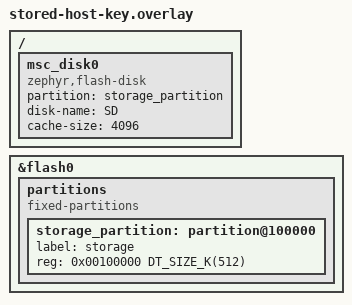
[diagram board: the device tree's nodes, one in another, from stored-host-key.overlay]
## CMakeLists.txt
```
# The wolfSSH provider on a real socket: an image for OpenSSH on the host to reach, and the conformance
# cases of tests/ssh with a scripted client in the same image. scripts/test-ssh-provider.sh drives it.
# Test only. The Access ports here are fakes: see src/test_access_ports.c.
cmake_minimum_required(VERSION 3.20.0)
list(APPEND EXTRA_CONF_FILE
    "${CMAKE_CURRENT_LIST_DIR}/../../../components/ssh/ports/zephyr/wolf-ssh.conf")
# The host key from the credential store on its PSA ports, in place of a key generated at each boot.
option(CRUX_SSH_TEST_STORED_HOST_KEY "Serve the host key from the credential store" OFF)
if(CRUX_SSH_TEST_STORED_HOST_KEY)
    list(APPEND EXTRA_CONF_FILE "${CMAKE_CURRENT_LIST_DIR}/stored-host-key.conf")
    list(APPEND EXTRA_DTC_OVERLAY_FILE "${CMAKE_CURRENT_LIST_DIR}/stored-host-key.overlay")
endif()
find_package(Zephyr REQUIRED HINTS $ENV{ZEPHYR_BASE})
project(crux_ssh_provider_test)

include(../../../components/ssh/ports/zephyr/wolf_ssh_settings.cmake)
crux_ssh_wolf_settings()
target_compile_definitions(crux_ssh_wolf_provider PRIVATE CRUX_SSH_WOLF_TESTING=1)
if(DEFINED CRUX_SSH_TEST_WINDOW_BYTES)
    target_compile_definitions(crux_ssh_wolf_provider PRIVATE
        CRUX_SSH_WOLF_WINDOW_BYTES=${CRUX_SSH_TEST_WINDOW_BYTES})
endif()
if(CRUX_SSH_TEST_OFFER_MLKEM)
    target_compile_definitions(crux_ssh_wolf_provider PRIVATE CRUX_SSH_WOLF_OFFER_MLKEM=1)
endif()

set(repository "${CMAKE_CURRENT_LIST_DIR}/../../..")
target_sources(app PRIVATE
    src/main.c
    src/test_access_ports.c
    src/test_keys.c
    src/test_sessions.c
    "${repository}/components/access/src/access.c"
    "${repository}/components/access/src/access_accounts.c"
    "${repository}/components/access/src/access_delay.c"
    "${repository}/components/access/src/access_login.c"
    "${repository}/components/access/src/access_record.c"
    "${repository}/components/access/src/access_session.c")
target_include_directories(app PRIVATE
    src
    "${repository}/components/access/include"
    "${repository}/components/access/adapter"
    "${repository}/components/access/src"
    "${repository}/components/ssh/adapter"
    "${repository}/components/ssh/ports/zephyr")
target_compile_definitions(app PRIVATE CRUX_SSH_WOLF_TESTING=1)
target_link_libraries(app PRIVATE crux::sync)

if(CRUX_SSH_TEST_STORED_HOST_KEY)
    if(NOT CONFIG_BOARD_NATIVE_SIM OR NOT CONFIG_WOLFPSA)
        message(FATAL_ERROR "The stored host key image is for native_sim on wolfPSA: its random "
                            "numbers come from a test generator")
    endif()
    # One wolfCrypt under wolfPSA and wolfSSH, as in tests/native/management_composition.
    include("${repository}/tests/psa_crypto/provider_declarations.cmake")
    target_compile_definitions(wolfSSL INTERFACE ${CRUX_PSA_WOLFCRYPT_DEFINITIONS})
    include("${repository}/components/ssh/access/sources.cmake")
    target_sources(app PRIVATE
        src/stored_host_key.c
        ${CRUX_SSH_HOST_KEY_SOURCES}
        "${repository}/components/credential/src/credential_image.c"
        "${repository}/components/credential/src/credential_store.c"
        "${repository}/components/credential/ports/psa/credential_psa.c"
        "${repository}/components/credential/ports/zephyr/credential_device_id.c")
    target_include_directories(app PRIVATE
        ${CRUX_SSH_HOST_KEY_INCLUDES}
        "${repository}/components/credential/src"
        "${repository}/components/credential/ports/psa"
        "${repository}/components/file/ports/zephyr")
    target_compile_definitions(app PRIVATE CRUX_SSH_TEST_STORED_HOST_KEY=1)
    target_link_libraries(app PRIVATE crux::file)
endif()

# The scripted client and the cases run on the host-reachable socket, so only on native_sim.
if(CONFIG_ARCH_POSIX)
    target_sources(app PRIVATE src/conformance_client.c "${repository}/tests/ssh/conformance.c")
    target_include_directories(app PRIVATE "${repository}/tests/ssh")
endif()
```

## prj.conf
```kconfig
# Shared by every build of this test image. Each stack and the arena are for this test: see
# docs/ssh-wolf-provider.md for what they were measured to need.
CONFIG_MAIN_STACK_SIZE=32768
CONFIG_COMMON_LIBC_MALLOC_ARENA_SIZE=524288
CONFIG_SYS_HEAP_RUNTIME_STATS=y
CONFIG_INIT_STACKS=y
CONFIG_THREAD_STACK_INFO=y
CONFIG_NETWORKING=y
CONFIG_NET_IPV4=y
CONFIG_NET_IPV6=n
CONFIG_NET_TCP=y
CONFIG_NET_SOCKETS=y
CONFIG_ZVFS_OPEN_MAX=32
CONFIG_ZVFS_POLL_MAX=8
CONFIG_NET_MAX_CONTEXTS=16
CONFIG_NET_SOCKETS_SOCKOPT_TLS=n
CONFIG_TLS_CREDENTIALS=n
CONFIG_MBEDTLS=n
CONFIG_CRUX_SYNC=y
CONFIG_CRUX_SYNC_MUTEX_COUNT=8
CONFIG_TEST_RANDOM_GENERATOR=y
```

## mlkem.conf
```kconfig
# Offers mlkem768x25519-sha256, to measure its cost. Off by default: see docs/ssh-wolf-provider.md.
CONFIG_WOLFSSL_MLKEM=y
```

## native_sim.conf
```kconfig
# The SSH test image on native_sim, as in tests/zephyr/ssh_wolf_probe: wolfSSH without the TLS socket
# backend on an unpatched Zephyr, and OpenSSH on the host reaching it through the native socket offload.
CONFIG_POSIX_API=n
CONFIG_POSIX_TIMERS=n
CONFIG_POSIX_THREADS=n
CONFIG_POSIX_SYSTEM_INTERFACES=y
CONFIG_NET_DRIVERS=y
CONFIG_NET_SOCKETS_OFFLOAD=y
CONFIG_NET_NATIVE_OFFLOADED_SOCKETS=y
CONFIG_ETH_NATIVE_TAP=n
# Sim time must follow the wall clock, or a limit would pass in no time for a client on the host.
CONFIG_NATIVE_SIM_SLOWDOWN_TO_REAL_TIME=y
```

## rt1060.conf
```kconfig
# RT1060-EVKB, compile only. No image from this build is flashed or run.
CONFIG_POSIX_API=y
CONFIG_POSIX_TIMERS=y
CONFIG_POSIX_THREADS=y
CONFIG_NET_L2_ETHERNET=y
CONFIG_ETH_DRIVER=y
```

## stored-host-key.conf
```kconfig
# Added by -DCRUX_SSH_TEST_STORED_HOST_KEY=ON, on native_sim only: the host key from the credential store
# on its PSA ports over wolfPSA, and the store on FatFs over the flash simulator's host file. TEST ONLY:
# the random numbers come from native_sim's test generator. See docs/ssh-wolf-provider.md.
CONFIG_PSA_CRYPTO=y
CONFIG_PSA_CRYPTO_PROVIDER_CUSTOM=y
CONFIG_PSA_WANT_ALG_SHA_256=y
CONFIG_PSA_WANT_ALG_GCM=y
CONFIG_PSA_WANT_KEY_TYPE_AES=y
CONFIG_PSA_WANT_ALG_ECDSA=y
CONFIG_PSA_WANT_KEY_TYPE_ECC_PUBLIC_KEY=y
CONFIG_PSA_WANT_KEY_TYPE_ECC_KEY_PAIR_IMPORT=y
CONFIG_PSA_WANT_KEY_TYPE_ECC_KEY_PAIR_EXPORT=y
CONFIG_PSA_WANT_KEY_TYPE_ECC_KEY_PAIR_GENERATE=y
CONFIG_PSA_WANT_ECC_SECP_R1_256=y
CONFIG_HWINFO=y

CONFIG_FILE_SYSTEM=y
CONFIG_FILE_SYSTEM_MKFS=y
CONFIG_FAT_FILESYSTEM_ELM=y
CONFIG_FS_FATFS_LFN=y
CONFIG_FS_FATFS_LFN_MODE_STACK=y
CONFIG_FS_FATFS_MAX_LFN=127
CONFIG_FS_FATFS_MOUNT_MKFS=n
CONFIG_FS_FATFS_REENTRANT=y
CONFIG_FS_FATFS_NUM_FILES=6
CONFIG_DISK_DRIVERS=y
CONFIG_DISK_DRIVER_FLASH=y
CONFIG_CRUX_FILE_FATFS_SIMULATOR=y
```

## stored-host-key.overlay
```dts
/* SPDX-License-Identifier: Apache-2.0 */
/* Added by -DCRUX_SSH_TEST_STORED_HOST_KEY=ON: a disk on the flash simulator, backed by a host file,
 * so that the credential store outlives each process. */
/delete-node/ &storage_partition;

&flash0 {
    partitions {
        compatible = "fixed-partitions";
        #address-cells = <1>;
        #size-cells = <1>;

        storage_partition: partition@100000 {
            label = "storage";
            reg = <0x00100000 DT_SIZE_K(512)>;
        };
    };
};

/ {
    msc_disk0 {
        status = "okay";
        compatible = "zephyr,flash-disk";
        partition = <&storage_partition>;
        disk-name = "SD";
        cache-size = <4096>;
    };
};
```

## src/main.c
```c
/*
 * The test image. With no arguments it serves SSH for scripts/test-ssh-provider.sh, with the access
 * adapter of #192 on the test ports, and stand-ins for the CLI and SFTP. With "conformance" it runs
 * the cases of tests/ssh on the provider with a scripted client. TEST ONLY. It prints what a test
 * on the host reads, and it is never flashed or run on a board.
 */
#include "crux_access_adapter.h"
#include "crux_ssh_callbacks.h"
#include "crux_ssh_wolf_provider.h"
#include "test_support.h"

#include <zephyr/kernel.h>
#include <zephyr/sys/printk.h>

#include <stdlib.h>
#include <string.h>

#ifdef CONFIG_ARCH_POSIX
#include "cmdline.h"
#include "nsi_main.h"
#endif

#define KEYS_MAX 4
#define KEY_BLOB_MAX 192u

static const char *const administrator_permissions[] = {CRUX_ACCESS_PERMISSION_MANAGE};
static const crux_access_role_t roles[] = {{"administrator", administrator_permissions, 1}};
static const crux_access_policy_t policy = {roles, 1, 15u * 60u, 8u * 3600u, NULL};

static struct {
    const char *mode;
    const char *only_case;
    const char *user;
    const char *password;
    const char *keys[KEYS_MAX];
    size_t key_count;
    crux_ssh_key_type_t host_key_type;
    bool repository_stand_ins;
    bool format;
    crux_ssh_config_t config;
} options = {
    .mode = "serve",
    .user = "operator",
    .password = "correct horse battery",
    .host_key_type = CRUX_SSH_KEY_ED25519,
    .config = {.port = 2222,
               .max_connections = 2,
               .max_auth_attempts = 3,
               .auth_timeout_ms = 3000,
               .io_timeout_ms = 200},
};

static test_key_t host_key;

static void finish(int status)
{
    printk("EXIT %d\n", status);
#ifdef CONFIG_ARCH_POSIX
    nsi_exit(status);
#endif
}

#ifdef CONFIG_ARCH_POSIX
static void parse_arguments(void)
{
    int argc = 0;
    char **argv = NULL;

    native_get_test_cmd_line_args(&argc, &argv);
    for (int i = 0; i < argc; ++i) {
        const char *value = strchr(argv[i], '=');

        value = value != NULL ? value + 1 : "";
        if (strcmp(argv[i], "conformance") == 0) {
            options.mode = "conformance";
        } else if (strncmp(argv[i], "only=", 5) == 0) {
            options.only_case = value;
        } else if (strncmp(argv[i], "key=", 4) == 0 && options.key_count < KEYS_MAX) {
            options.keys[options.key_count++] = value;
        } else if (strcmp(argv[i], "host=ecdsa") == 0) {
            options.host_key_type = CRUX_SSH_KEY_ECDSA_P256;
        } else if (strcmp(argv[i], "format") == 0) {
            options.format = true;
        } else if (strcmp(argv[i], "stand-ins=repository") == 0) {
            options.repository_stand_ins = true;
        } else if (strncmp(argv[i], "connections=", 12) == 0) {
            options.config.max_connections = (uint8_t)atoi(value);
        } else if (strncmp(argv[i], "attempts=", 9) == 0) {
            options.config.max_auth_attempts = (uint8_t)atoi(value);
        } else if (strncmp(argv[i], "send-block=", 11) == 0) {
            crux_ssh_wolf_test_block_sends((unsigned)atoi(value));
        } else if (strncmp(argv[i], "auth-ms=", 8) == 0) {
            options.config.auth_timeout_ms = (uint32_t)atoi(value);
        }
    }
}
#else
static void parse_arguments(void)
{
}
#endif

static int hex_value(char digit)
{
    if (digit >= '0' && digit <= '9') {
        return digit - '0';
    }
    return digit >= 'a' && digit <= 'f' ? digit - 'a' + 10 : -1;
}

static size_t decode_hex(const char *text, uint8_t *out, size_t capacity)
{
    size_t length = strlen(text) / 2u;

    if (length > capacity) {
        return 0u;
    }
    for (size_t i = 0; i < length; ++i) {
        int high = hex_value(text[2u * i]);
        int low = hex_value(text[2u * i + 1u]);

        if (high < 0 || low < 0) {
            return 0u;
        }
        out[i] = (uint8_t)(high * 16 + low);
    }
    return length;
}

static bool set_up_accounts(void)
{
    static const crux_access_origin_t serial = {.channel = CRUX_ACCESS_CHANNEL_SERIAL};
    crux_access_session_t session = {0};
    uint32_t retry_after_ms = 0;
    size_t password_length = strlen(options.password);

    if (crux_access_init(&policy) != CRUX_ACCESS_OK ||
        crux_access_provision_first_account(options.user, options.password, password_length,
                                            "administrator", &serial) != CRUX_ACCESS_OK ||
        crux_access_login_password(options.user, options.password, password_length, &serial,
                                   &session, &retry_after_ms) != CRUX_ACCESS_OK) {
        return false;
    }
    for (size_t i = 0; i < options.key_count; ++i) {
        uint8_t blob[KEY_BLOB_MAX];
        size_t length = decode_hex(options.keys[i], blob, sizeof(blob));

        if (length == 0u ||
            crux_access_account_add_key(session, options.user, blob, length) != CRUX_ACCESS_OK) {
            return false;
        }
    }
    crux_access_logout(&session);
    return true;
}

static bool host_key_ready(void)
{
#ifdef CRUX_SSH_TEST_STORED_HOST_KEY
    return test_stored_host_key_load(options.host_key_type, options.format, &host_key);
#else
    return test_key_generate(options.host_key_type, &host_key);
#endif
}

static int serve(void)
{
    crux_ssh_callbacks_t callbacks = *crux_ssh_callback_table();
    crux_status_t status;

    if (!set_up_accounts() || !host_key_ready()) {
        printk("SETUP failed\n");
        return 2;
    }
    if (!options.repository_stand_ins) {
        test_sessions_fill(&callbacks);
    }
    options.config.host_key_type = host_key.type;
    options.config.host_key = host_key.host_key;
    options.config.host_key_length = host_key.host_key_length;
    test_key_print_fingerprint(&host_key);
    status = crux_ssh_wolf_provider()->start(&options.config, &callbacks);
    if (status != CRUX_OK) {
        printk("START failed %d\n", (int)status);
        return 3;
    }
    printk("READY port=%u\n", options.config.port);
    test_sessions_wait_for_stop();
    status = crux_ssh_wolf_provider()->stop();
    printk("STOPPED %d\n", (int)status);
    test_print_measurements();
    return status == CRUX_OK ? 0 : 4;
}

int main(void)
{
    parse_arguments();
#ifdef CONFIG_ARCH_POSIX
    if (strcmp(options.mode, "conformance") == 0) {
        finish(test_conformance_run(options.only_case));
        return 0;
    }
#endif
    finish(serve());
    return 0;
}
```

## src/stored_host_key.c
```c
/*
 * The host key from the credential store, for an image built with CRUX_SSH_TEST_STORED_HOST_KEY.
 * The store runs on its PSA ports over wolfPSA, on FatFs over the flash simulator, whose host file
 * outlives the process, so a test boots the image again on the same file and sees the same key.
 *
 * TEST ONLY. The random numbers come from native_sim's test generator and the device ID from its
 * hwinfo, so a stored key here protects nothing: see docs/psa-crypto-design.md. The image prints
 * the store's events and the fingerprint, and never the key.
 */
#include "credential_port.h"
#include "crux_ssh_access.h"
#include "file_native.h"
#include "test_support.h"

#include <crux_credential_adapter.h>

#include <ff.h>
#include <string.h>
#include <zephyr/fs/fs.h>
#include <zephyr/sys/printk.h>

enum { ROOT_SLOT_A = 1, ROOT_SLOT_B = 2 };
#define MOUNT_POINT "/SD:"
#define DISK_NAME "SD:"
#define PATH_SLOT_A MOUNT_POINT "/secure-a"
#define PATH_SLOT_B MOUNT_POINT "/secure-b"

static FATFS fat;
static struct fs_mount_t mount = {
    .type = FS_FATFS,
    .mnt_point = MOUNT_POINT,
    .fs_data = &fat,
    .flags = FS_MOUNT_FLAG_NO_FORMAT,
};

/* The store's events, which carry no record bytes, for the test on the host to read. */
void crux_credential_port_event(const crux_credential_event_t *event)
{
    static const char *const names[] = {"state",         "slot_invalid", "save_failed",
                                        "key_generated", "key_replaced", "erased"};
    const char *name =
        (size_t)event->type < sizeof(names) / sizeof(names[0]) ? names[event->type] : "unknown";

    printk("STORE event=credential.%s record=%d result=%d state=%d\n", name, (int)event->record,
           (int)event->result, (int)event->state);
}

static bool directory_ready(const char *path)
{
    int result = fs_mkdir(path);

    return result == 0 || result == -EEXIST;
}

/* Formats a blank disk only when the test asks, so that a test can also boot on a disk that does
 * not mount and see the store refuse. */
static bool medium_ready(bool format)
{
    if (fs_mount(&mount) != 0) {
        if (!format || fs_mkfs(FS_FATFS, (uintptr_t)DISK_NAME, NULL, 0) != 0 ||
            fs_mount(&mount) != 0) {
            return false;
        }
    }
    return directory_ready(PATH_SLOT_A) && directory_ready(PATH_SLOT_B) &&
           crux_file_zephyr_bind_root(ROOT_SLOT_A, PATH_SLOT_A) == CRUX_FILE_OK &&
           crux_file_zephyr_bind_root(ROOT_SLOT_B, PATH_SLOT_B) == CRUX_FILE_OK;
}

bool test_stored_host_key_load(crux_ssh_key_type_t type, bool format, test_key_t *key)
{
    crux_ssh_host_key_t host_key;
    crux_credential_result_t store;
    crux_status_t status;

    /* A medium that failed leaves the roots unbound, and the store then reads UNUSABLE. */
    if (!medium_ready(format)) {
        printk("STORE medium not ready\n");
    }
    store = crux_credential_start(ROOT_SLOT_A, ROOT_SLOT_B);
    printk("STORE start=%d state=%d\n", (int)store, (int)crux_credential_state());
    status = crux_ssh_host_key_load(type, &host_key);
    if (status != CRUX_OK) {
        printk("HOST-KEY unavailable status=%d\n", (int)status);
        return false;
    }
    memset(key, 0, sizeof(*key));
    key->type = host_key.type;
    key->host_key_length = host_key.length;
    memcpy(key->host_key, host_key.key, host_key.length);
    crux_ssh_host_key_clear(&host_key);
    return true;
}
```

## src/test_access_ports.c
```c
/*
 * crux_access ports for this test image: TEST ONLY, and declared as such in
 * docs/ssh-wolf-provider.md. The store is RAM, so accounts last one run. Random numbers come from
 * native_sim's test generator. The derivation and the keyed hash are real wolfCrypt, because a
 * client on the host needs a real login path, and neither is the PSA provider that #242 supplies.
 * Events print, so that a test on the host can read them.
 */
#include "test_support.h"

#include "access_port.h"

#include <zephyr/kernel.h>
#include <zephyr/random/random.h>
#include <zephyr/sys/printk.h>

#include <wolfssl/wolfcrypt/hmac.h>
#include <wolfssl/wolfcrypt/pwdbased.h>

#include <string.h>

static uint8_t record_bytes[CRUX_ACCESS_RECORD_SIZE_MAX];
static size_t record_length;
static int32_t derive_delay_ms;
static unsigned derive_count;

void test_access_derive_delay_ms(int32_t delay_ms)
{
    derive_delay_ms = delay_ms;
}

unsigned test_access_derive_count(void)
{
    return derive_count;
}

bool crux_access_port_derive(uint32_t algorithm, uint32_t iterations,
                             const uint8_t salt[CRUX_ACCESS_SALT_SIZE], const char *password,
                             size_t length, uint8_t derived[CRUX_ACCESS_DERIVED_SIZE])
{
    ++derive_count;
    printk("ACCESS derive count=%u\n", derive_count);
    if (algorithm != CRUX_ACCESS_VERIFIER_PBKDF2_HMAC_SHA256) {
        return false;
    }
    /* CPU work takes no simulated time, so a slow verifier on a board is modelled by a sleep. */
    if (derive_delay_ms > 0) {
        k_msleep(derive_delay_ms);
    }
    return wc_PBKDF2(derived, (const byte *)password, (int)length, salt, CRUX_ACCESS_SALT_SIZE,
                     (int)iterations, CRUX_ACCESS_DERIVED_SIZE, WC_SHA256) == 0;
}

bool crux_access_port_random(uint8_t *output, size_t length)
{
    sys_rand_get(output, length);
    return true;
}

bool crux_access_port_hmac(const uint8_t key[CRUX_ACCESS_HASH_KEY_SIZE], const uint8_t *data,
                           size_t length, uint8_t hash[CRUX_ACCESS_HASH_SIZE])
{
    Hmac hmac;
    int result = wc_HmacInit(&hmac, NULL, INVALID_DEVID);

    if (result == 0) {
        result = wc_HmacSetKey(&hmac, WC_SHA256, key, CRUX_ACCESS_HASH_KEY_SIZE);
    }
    if (result == 0) {
        result = wc_HmacUpdate(&hmac, data, (word32)length);
    }
    if (result == 0) {
        result = wc_HmacFinal(&hmac, hash);
    }
    wc_HmacFree(&hmac);
    return result == 0;
}

uint64_t crux_access_port_now_ms(void)
{
    return (uint64_t)k_uptime_get();
}

crux_access_store_state_t crux_access_port_store_load(uint8_t *record, size_t capacity,
                                                      size_t *length)
{
    if (record_length == 0u) {
        return CRUX_ACCESS_STORE_EMPTY;
    }
    if (record_length > capacity) {
        return CRUX_ACCESS_STORE_UNUSABLE;
    }
    memcpy(record, record_bytes, record_length);
    *length = record_length;
    return CRUX_ACCESS_STORE_VALID;
}

bool crux_access_port_store_save(const uint8_t *record, size_t length)
{
    if (length > sizeof(record_bytes)) {
        return false;
    }
    memcpy(record_bytes, record, length);
    record_length = length;
    return true;
}

static const char *event_name(crux_access_event_type_t type)
{
    switch (type) {
    case CRUX_ACCESS_EVENT_LOGIN_SUCCESS:
        return "LOGIN_SUCCESS";
    case CRUX_ACCESS_EVENT_LOGIN_FAILURE:
        return "LOGIN_FAILURE";
    case CRUX_ACCESS_EVENT_KEY_FAILURE:
        return "KEY_FAILURE";
    case CRUX_ACCESS_EVENT_DELAY_APPLIED:
        return "DELAY_APPLIED";
    case CRUX_ACCESS_EVENT_LOGOUT:
        return "LOGOUT";
    case CRUX_ACCESS_EVENT_LOGIN_BUSY:
        return "LOGIN_BUSY";
    case CRUX_ACCESS_EVENT_LOGIN_NO_SESSION:
        return "LOGIN_NO_SESSION";
    case CRUX_ACCESS_EVENT_LOGIN_REFUSED:
        return "LOGIN_REFUSED";
    default:
        return "OTHER";
    }
}

void crux_access_port_event(const crux_access_event_t *event)
{
    printk("ACCESS event type=%s result=%d channel=%d source_length=%u account=%s\n",
           event_name(event->type), (int)event->result, (int)event->origin.channel,
           (unsigned)event->origin.source_length, event->account);
}
```

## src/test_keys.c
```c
/* Host and user keys for this test image, generated at each boot. TEST ONLY. */
#include "crux_ssh_wolf_provider.h"
#include "test_support.h"

#include <zephyr/sys/byteorder.h>
#include <zephyr/sys/printk.h>

#include <wolfssl/wolfcrypt/asn_public.h>
#include <wolfssl/wolfcrypt/ecc.h>
#include <wolfssl/wolfcrypt/ed25519.h>
#include <wolfssl/wolfcrypt/hash.h>
#include <wolfssl/wolfcrypt/random.h>
#include <wolfssl/wolfcrypt/sha256.h>

#include <string.h>

static WC_RNG rng;
static bool rng_ready;

static bool rng_get(void)
{
    if (!rng_ready) {
        rng_ready = wc_InitRng(&rng) == 0;
    }
    return rng_ready;
}

static size_t put_string(uint8_t *out, const void *text, size_t length)
{
    sys_put_be32((uint32_t)length, out);
    memcpy(out + 4, text, length);
    return 4u + length;
}

static bool generate_ed25519(test_key_t *key)
{
    ed25519_key wolf_key;
    word32 private_length = 32u;
    word32 public_length = 32u;
    bool done;

    if (wc_ed25519_init(&wolf_key) != 0) {
        return false;
    }
    done = wc_ed25519_make_key(&rng, ED25519_KEY_SIZE, &wolf_key) == 0 &&
           wc_ed25519_export_private_only(&wolf_key, key->host_key, &private_length) == 0 &&
           wc_ed25519_export_public(&wolf_key, key->host_key + 32, &public_length) == 0;
    wc_ed25519_free(&wolf_key);
    key->host_key_length = 64u;
    key->blob_length = put_string(key->blob, "ssh-ed25519", 11u);
    key->blob_length += put_string(key->blob + key->blob_length, key->host_key + 32, 32u);
    return done;
}

static bool generate_p256(test_key_t *key)
{
    ecc_key wolf_key;
    word32 private_length = 32u;
    word32 public_length = 65u;
    bool done;

    if (wc_ecc_init(&wolf_key) != 0) {
        return false;
    }
    done = wc_ecc_make_key_ex(&rng, 32, &wolf_key, ECC_SECP256R1) == 0 &&
           wc_ecc_export_private_only(&wolf_key, key->host_key, &private_length) == 0 &&
           private_length == 32u &&
           wc_ecc_export_x963(&wolf_key, key->host_key + 32, &public_length) == 0;
    wc_ecc_free(&wolf_key);
    key->host_key_length = 97u;
    key->blob_length = put_string(key->blob, "ecdsa-sha2-nistp256", 19u);
    key->blob_length += put_string(key->blob + key->blob_length, "nistp256", 8u);
    key->blob_length += put_string(key->blob + key->blob_length, key->host_key + 32, 65u);
    return done;
}

bool test_key_generate(crux_ssh_key_type_t type, test_key_t *key)
{
    memset(key, 0, sizeof(*key));
    key->type = type;
    if (!rng_get()) {
        return false;
    }
    return type == CRUX_SSH_KEY_ED25519 ? generate_ed25519(key) : generate_p256(key);
}

static bool sign_ed25519(const test_key_t *key, const uint8_t *data, size_t length, uint8_t *out,
                         word32 *out_length)
{
    ed25519_key wolf_key;
    bool done;

    if (wc_ed25519_init(&wolf_key) != 0) {
        return false;
    }
    done = wc_ed25519_import_private_key(key->host_key, 32u, key->host_key + 32, 32u, &wolf_key) ==
               0 &&
           wc_ed25519_sign_msg(data, (word32)length, out, out_length, &wolf_key) == 0;
    wc_ed25519_free(&wolf_key);
    return done;
}

static size_t put_mpint(uint8_t *out, const uint8_t *value, size_t length)
{
    size_t lead = (length > 0u && (value[0] & 0x80u) != 0u) ? 1u : 0u;

    sys_put_be32((uint32_t)(length + lead), out);
    out[4] = 0u;
    memcpy(out + 4 + lead, value, length);
    return 4u + lead + length;
}

static bool sign_p256(const test_key_t *key, const uint8_t *data, size_t length, uint8_t *out,
                      word32 *out_length, bool good_signature)
{
    ecc_key wolf_key;
    uint8_t digest[WC_SHA256_DIGEST_SIZE];
    uint8_t der[80];
    uint8_t r[33];
    uint8_t s[33];
    word32 der_length = sizeof(der);
    word32 r_length = sizeof(r);
    word32 s_length = sizeof(s);
    bool done;

    if (wc_ecc_init(&wolf_key) != 0) {
        return false;
    }
    done = wc_Sha256Hash(data, (word32)length, digest) == 0 &&
           wc_ecc_import_private_key_ex(key->host_key, 32u, key->host_key + 32, 65u, &wolf_key,
                                        ECC_SECP256R1) == 0 &&
           wc_ecc_set_rng(&wolf_key, &rng) == 0 &&
           wc_ecc_sign_hash(digest, sizeof(digest), der, &der_length, &rng, &wolf_key) == 0 &&
           wc_ecc_sig_to_rs(der, der_length, r, &r_length, s, &s_length) == 0;
    wc_ecc_free(&wolf_key);
    if (!done) {
        return false;
    }
    if (!good_signature) {
        r[r_length - 1u] ^= 0x01u;
    }
    *out_length = (word32)put_mpint(out, r, r_length);
    *out_length += (word32)put_mpint(out + *out_length, s, s_length);
    return true;
}

bool test_key_sign(const test_key_t *key, const char *algorithm, const uint8_t *data, size_t length,
                   bool good_signature, uint8_t *signature, size_t capacity, size_t *written)
{
    uint8_t body[96];
    word32 body_length = sizeof(body);
    size_t at;

    if (key->type == CRUX_SSH_KEY_ED25519) {
        if (!sign_ed25519(key, data, length, body, &body_length)) {
            return false;
        }
        if (!good_signature) {
            body[body_length - 1u] ^= 0x01u;
        }
    } else if (!sign_p256(key, data, length, body, &body_length, good_signature)) {
        return false;
    }
    if (capacity < 8u + strlen(algorithm) + body_length) {
        return false;
    }
    at = put_string(signature, algorithm, strlen(algorithm));
    at += put_string(signature + at, body, body_length);
    *written = at;
    return true;
}

void test_key_print_fingerprint(const test_key_t *key)
{
    char fingerprint[CRUX_SSH_WOLF_FINGERPRINT_SIZE];

    if (crux_ssh_wolf_host_key_fingerprint(key->type, key->host_key, key->host_key_length,
                                           fingerprint, sizeof(fingerprint)) == CRUX_OK) {
        printk("HOST-KEY %s\n", fingerprint);
    } else {
        printk("HOST-KEY unavailable\n");
    }
}
```

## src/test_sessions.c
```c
/*
 * Stand-ins for the CLI of #193 and the SFTP adapter of #194, so that OpenSSH can exercise the
 * channel functions, the exit status and the close. TEST ONLY: none of these commands exists in
 * Crux.
 */
#include "crux_ssh_attachment.h"
#include "crux_ssh_wolf_provider.h"
#include "test_support.h"

#include <zephyr/kernel.h>
#include <zephyr/sys/printk.h>
#include <zephyr/sys/sys_heap.h>

#include <stdlib.h>
#include <string.h>

struct crux_ssh_file_handle {
    int id;
};

/* In Zephyr's malloc.c, with no header of its own at this revision. */
int malloc_runtime_stats_get(struct sys_memory_stats *stats);

static K_SEM_DEFINE(stop_requested, 0, 1);
static struct crux_ssh_file_handle file_handles[CRUX_SSH_WOLF_CONNECTIONS_MAX];
static atomic_t next_handle;

static crux_status_t write_all(crux_ssh_channel_t *channel, const void *data, size_t length)
{
    const crux_ssh_provider_t *provider = crux_ssh_wolf_provider();
    const char *at = data;

    while (length > 0u) {
        size_t written = 0;
        crux_status_t status = provider->write(channel, at, length, &written);

        if (status == CRUX_ERR_TIMEOUT) {
            continue;
        }
        if (status != CRUX_OK) {
            return status;
        }
        at += written;
        length -= written;
    }
    return CRUX_OK;
}

static crux_status_t write_text(crux_ssh_channel_t *channel, const char *text)
{
    return write_all(channel, text, strlen(text));
}

static int echo_until_end(crux_ssh_channel_t *channel)
{
    const crux_ssh_provider_t *provider = crux_ssh_wolf_provider();
    char buffer[256];

    while (true) {
        size_t count = 0;
        crux_status_t status = provider->read(channel, buffer, sizeof(buffer), &count);

        if (status == CRUX_ERR_TIMEOUT) {
            continue;
        }
        if (status != CRUX_OK) {
            return status == CRUX_ERR_NO_DATA ? 0 : 1;
        }
        if (write_all(channel, buffer, count) != CRUX_OK) {
            return 1;
        }
    }
}

static int send_pattern(crux_ssh_channel_t *channel, size_t length)
{
    char block[512];

    for (size_t i = 0; i < sizeof(block); ++i) {
        block[i] = (char)('a' + i % 26u);
    }
    while (length > 0u) {
        size_t piece = MIN(length, sizeof(block));

        if (write_all(channel, block, piece) != CRUX_OK) {
            return 1;
        }
        length -= piece;
    }
    return 0;
}

static int print_user(crux_ssh_attachment_t *attachment, crux_ssh_channel_t *channel)
{
    crux_access_session_t session = crux_ssh_attachment_session(attachment);
    char user[CRUX_ACCESS_NAME_SIZE];
    char role[CRUX_ACCESS_NAME_SIZE];

    if (crux_access_session_user(session, user, sizeof(user)) != CRUX_ACCESS_OK ||
        crux_access_session_role(session, role, sizeof(role)) != CRUX_ACCESS_OK) {
        return 1;
    }
    (void)write_text(channel, user);
    (void)write_text(channel, " ");
    (void)write_text(channel, role);
    (void)write_text(channel, "\n");
    return 0;
}

void test_print_measurements(void)
{
    struct sys_memory_stats stats = {0};
    size_t worker = 0;
    size_t listener = 0;

    (void)malloc_runtime_stats_get(&stats);
    crux_ssh_wolf_test_stack_used(&worker, &listener);
    printk("MEASURE heap_allocated=%zu heap_peak=%zu heap_free=%zu worker_stack_used=%zu "
           "listener_stack_used=%zu\n",
           stats.allocated_bytes, stats.max_allocated_bytes, stats.free_bytes, worker, listener);
}

static int test_exec(void *context, crux_ssh_attachment_t *attachment, crux_ssh_channel_t *channel,
                     const char *command, size_t command_length)
{
    ARG_UNUSED(context);
    ARG_UNUSED(command_length);
    if (strcmp(command, "whoami") == 0) {
        return print_user(attachment, channel);
    }
    if (strncmp(command, "exit ", 5) == 0) {
        return atoi(command + 5);
    }
    if (strncmp(command, "output ", 7) == 0) {
        return send_pattern(channel, (size_t)atoi(command + 7));
    }
    if (strcmp(command, "cat") == 0) {
        return echo_until_end(channel);
    }
    if (strncmp(command, "sleep ", 6) == 0) {
        k_msleep(atoi(command + 6));
        return 0;
    }
    if (strncmp(command, "derive-delay ", 13) == 0) {
        test_access_derive_delay_ms(atoi(command + 13));
        return 0;
    }
    if (strcmp(command, "measure") == 0) {
        test_print_measurements();
        return 0;
    }
    if (strcmp(command, "stop") == 0) {
        k_sem_give(&stop_requested);
        return 0;
    }
    (void)write_text(channel, "unknown test command\n");
    return 127;
}

static int test_shell(void *context, crux_ssh_attachment_t *attachment, crux_ssh_channel_t *channel,
                      bool terminal)
{
    ARG_UNUSED(context);
    ARG_UNUSED(attachment);
    (void)write_text(channel, terminal ? "terminal=1\r\n" : "terminal=0\n");
    return echo_until_end(channel);
}

static crux_status_t test_sftp_open(void *context, crux_ssh_attachment_t *attachment,
                                    crux_ssh_file_handle_t **handle)
{
    ARG_UNUSED(context);
    ARG_UNUSED(attachment);
    /* Every operation of the refusing port in components/ssh/sftp/port fails behind this handle. */
    *handle = &file_handles[(size_t)atomic_inc(&next_handle) % ARRAY_SIZE(file_handles)];
    printk("SFTP open\n");
    return CRUX_OK;
}

static void test_sftp_close(void *context, crux_ssh_attachment_t *attachment,
                            crux_ssh_file_handle_t *handle)
{
    ARG_UNUSED(context);
    ARG_UNUSED(attachment);
    ARG_UNUSED(handle);
    printk("SFTP close\n");
}

void test_sessions_fill(crux_ssh_callbacks_t *callbacks)
{
    callbacks->shell = test_shell;
    callbacks->exec = test_exec;
    callbacks->sftp_open = test_sftp_open;
    callbacks->sftp_close = test_sftp_close;
}

void test_sessions_wait_for_stop(void)
{
    (void)k_sem_take(&stop_requested, K_FOREVER);
}
```

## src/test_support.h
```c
/* What the parts of this test image share. Test only. */
#ifndef CRUX_SSH_PROVIDER_TEST_SUPPORT_H
#define CRUX_SSH_PROVIDER_TEST_SUPPORT_H

#include "crux_ssh_provider.h"

#include <stdbool.h>
#include <stddef.h>
#include <stdint.h>

/* test_access_ports.c */
void test_access_derive_delay_ms(int32_t delay_ms);
unsigned test_access_derive_count(void);

/* test_keys.c: keys from wolfCrypt on native_sim's test-only entropy, never stored. */
typedef struct {
    crux_ssh_key_type_t type;
    uint8_t host_key[97]; /* The provider's form: private part, then public part. */
    size_t host_key_length;
    uint8_t blob[128]; /* The SSH public key blob. */
    size_t blob_length;
} test_key_t;

bool test_key_generate(crux_ssh_key_type_t type, test_key_t *key);
/* Signs data as a user key signs a login request, with the SSH signature blob as the result. */
bool test_key_sign(const test_key_t *key, const char *algorithm, const uint8_t *data, size_t length,
                   bool good_signature, uint8_t *signature, size_t capacity, size_t *written);
void test_key_print_fingerprint(const test_key_t *key);

/* stored_host_key.c, in an image built with CRUX_SSH_TEST_STORED_HOST_KEY: the host key from the
 * credential store on its PSA ports. format makes a file system on a disk that does not mount. */
bool test_stored_host_key_load(crux_ssh_key_type_t type, bool format, test_key_t *key);

/* test_sessions.c: stand-ins for the CLI of #193 and the SFTP adapter of #194. */
void test_sessions_fill(crux_ssh_callbacks_t *callbacks);
void test_sessions_wait_for_stop(void);
void test_print_measurements(void);

/* conformance_client.c */
int test_conformance_run(const char *only);

#endif /* CRUX_SSH_PROVIDER_TEST_SUPPORT_H */
```
